AUTOSAR XML (schema 4-1-3)
standard types defined: uint16, uint32, uint16_DataConstr, uint32_DataConstr, boolean, uint8
package /UAES/ASW/CompuMethods
  compu method CM_boolean: 0=FALSE, 1=TRUE
package /UAES/ASW/DataConstrs
  range DC_boolean: raw 0..1
  range DC_uint16: phys 0..6553.5, raw 0..65535
package /UAES/ASW/DataTypeMappingSets
  data type mapping set DTMS_HvacBlowr_DD
package /UAES/ASW/PortInterfaces
  client server interface IoHwAb_IoSigDio
    operation Di_Get: possible-error=IoHwAb_IoSigDio/E_NOT_OK
      arg id_u16: type=ImplementationDataTypes/uint16, direction=IN, server-argument-impl-policy=USE-ARGUMENT-TYPE
      arg val_u8: type=uint8, direction=OUT, server-argument-impl-policy=USE-ARGUMENT-TYPE
    operation Do_Set: possible-error=IoHwAb_IoSigDio/E_NOT_OK
      arg id_u16: type=ImplementationDataTypes/uint16, direction=IN, server-argument-impl-policy=USE-ARGUMENT-TYPE
      arg val_u8: type=uint8, direction=IN, server-argument-impl-policy=USE-ARGUMENT-TYPE
    error E_NOT_OK: error-code=1
  client server interface IoHwAb_IoSigPwm
    operation Pwm_SetDuty: possible-error=IoHwAb_IoSigPwm/E_NOT_OK
      arg id_u16: type=ImplementationDataTypes/uint16, direction=IN, server-argument-impl-policy=USE-ARGUMENT-TYPE
      arg duty_u16: type=ImplementationDataTypes/uint16, direction=IN, server-argument-impl-policy=USE-ARGUMENT-TYPE
    operation Pwm_SetPerd: possible-error=IoHwAb_IoSigPwm/E_NOT_OK
      arg id_u16: type=ImplementationDataTypes/uint16, direction=IN, server-argument-impl-policy=USE-ARGUMENT-TYPE
      arg perd_u32: type=uint32, direction=IN, server-argument-impl-policy=USE-ARGUMENT-TYPE
    operation Pwm_SetPerdAndDuty: possible-error=IoHwAb_IoSigPwm/E_NOT_OK
      arg id_u16: type=ImplementationDataTypes/uint16, direction=IN, server-argument-impl-policy=USE-ARGUMENT-TYPE
      arg perd_u32: type=uint32, direction=IN, server-argument-impl-policy=USE-ARGUMENT-TYPE
      arg duty_u16: type=ImplementationDataTypes/uint16, direction=IN, server-argument-impl-policy=USE-ARGUMENT-TYPE
    error E_NOT_OK: error-code=1
  13 x sender receiver interface:
    gCFG_u8BlowrCtrlFreqTyp: invalidation-policy{data-element=gCFG_u8BlowrCtrlFreqTyp/Val, handle-invalid=DONT-INVALIDATE}
      data Val: sw-calibration-access=READ-ONLY, type=uint8
    gCFG_u8BlowrCtrlTyp: invalidation-policy{data-element=gCFG_u8BlowrCtrlTyp/Val, handle-invalid=DONT-INVALIDATE}
      data Val: sw-calibration-access=READ-ONLY, type=uint8
    gCFG_u8ReBlowrCtrlFreqTyp: invalidation-policy{data-element=gCFG_u8ReBlowrCtrlFreqTyp/Val, handle-invalid=DONT-INVALIDATE}
      data Val: sw-calibration-access=READ-ONLY, type=uint8
    gCFG_u8ReBlowrCtrlTyp: invalidation-policy{data-element=gCFG_u8ReBlowrCtrlTyp/Val, handle-invalid=DONT-INVALIDATE}
      data Val: sw-calibration-access=READ-ONLY, type=uint8
    gPRM_u8VehicleTypeCfg: invalidation-policy{data-element=gPRM_u8VehicleTypeCfg/Val, handle-invalid=DONT-INVALIDATE}
      data Val: sw-calibration-access=READ-ONLY, range raw 0..255, type=uint8
    HvacBlowr_bLPMBlowrEna: invalidation-policy{data-element=HvacBlowr_bLPMBlowrEna/Val, handle-invalid=DONT-INVALIDATE}
      data Val: sw-calibration-access=READ-ONLY, type=boolean
    HvacBlowr_bReLPMBlowrEna: invalidation-policy{data-element=HvacBlowr_bReLPMBlowrEna/Val, handle-invalid=DONT-INVALIDATE}
      data Val: sw-calibration-access=READ-ONLY, type=boolean
    HvacBlowr_freqPWMBlowr: invalidation-policy{data-element=HvacBlowr_freqPWMBlowr/Val, handle-invalid=DONT-INVALIDATE}
      data Val: sw-calibration-access=READ-ONLY, type=ImplementationDataTypes/uint16
    HvacBlowr_freqRePWMBlowr: invalidation-policy{data-element=HvacBlowr_freqRePWMBlowr/Val, handle-invalid=DONT-INVALIDATE}
      data Val: sw-calibration-access=READ-ONLY, type=ImplementationDataTypes/uint16
    HvacBlowr_ratLPMBlowr: invalidation-policy{data-element=HvacBlowr_ratLPMBlowr/Val, handle-invalid=DONT-INVALIDATE}
      data Val: sw-calibration-access=READ-ONLY, type=ImplementationDataTypes/uint16
    HvacBlowr_ratPWMBlowr: invalidation-policy{data-element=HvacBlowr_ratPWMBlowr/Val, handle-invalid=DONT-INVALIDATE}
      data Val: sw-calibration-access=READ-ONLY, type=ImplementationDataTypes/uint16
    HvacBlowr_ratReLPMBlowr: invalidation-policy{data-element=HvacBlowr_ratReLPMBlowr/Val, handle-invalid=DONT-INVALIDATE}
      data Val: sw-calibration-access=READ-ONLY, type=ImplementationDataTypes/uint16
    HvacBlowr_ratRePWMBlowr: invalidation-policy{data-element=HvacBlowr_ratRePWMBlowr/Val, handle-invalid=DONT-INVALIDATE}
      data Val: sw-calibration-access=READ-ONLY, type=ImplementationDataTypes/uint16
package /UAES/ASW/SwComponentTypes
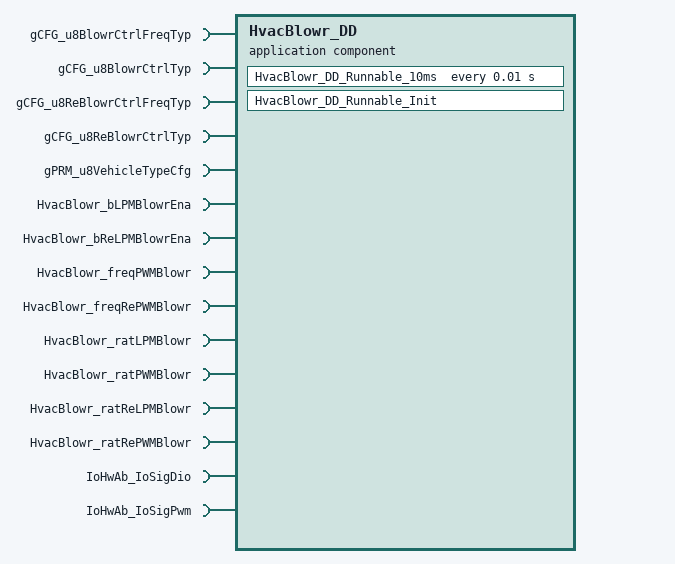
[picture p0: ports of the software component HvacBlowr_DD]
  application sw component type HvacBlowr_DD
    15 x require port:
      gCFG_u8BlowrCtrlFreqTyp: nonqueued-receiver-com-spec{data-element=gCFG_u8BlowrCtrlFreqTyp/Val, filter=data-filter-type=ALWAYS, init-value=0}, required-interface=gCFG_u8BlowrCtrlFreqTyp
      gCFG_u8BlowrCtrlTyp: nonqueued-receiver-com-spec{data-element=gCFG_u8BlowrCtrlTyp/Val, filter=data-filter-type=ALWAYS, init-value=0}, required-interface=gCFG_u8BlowrCtrlTyp
      gCFG_u8ReBlowrCtrlFreqTyp: nonqueued-receiver-com-spec{data-element=gCFG_u8ReBlowrCtrlFreqTyp/Val, filter=data-filter-type=ALWAYS, init-value=0}, required-interface=gCFG_u8ReBlowrCtrlFreqTyp
      gCFG_u8ReBlowrCtrlTyp: nonqueued-receiver-com-spec{data-element=gCFG_u8ReBlowrCtrlTyp/Val, filter=data-filter-type=ALWAYS, init-value=0}, required-interface=gCFG_u8ReBlowrCtrlTyp
      gPRM_u8VehicleTypeCfg: nonqueued-receiver-com-spec{data-element=gPRM_u8VehicleTypeCfg/Val, filter=data-filter-type=ALWAYS, init-value=0}, required-interface=gPRM_u8VehicleTypeCfg
      HvacBlowr_bLPMBlowrEna: nonqueued-receiver-com-spec{data-element=HvacBlowr_bLPMBlowrEna/Val, filter=data-filter-type=ALWAYS, init-value=0}, required-interface=HvacBlowr_bLPMBlowrEna
      HvacBlowr_bReLPMBlowrEna: nonqueued-receiver-com-spec{data-element=HvacBlowr_bReLPMBlowrEna/Val, filter=data-filter-type=ALWAYS, init-value=0}, required-interface=HvacBlowr_bReLPMBlowrEna
      HvacBlowr_freqPWMBlowr: nonqueued-receiver-com-spec{data-element=HvacBlowr_freqPWMBlowr/Val, filter=data-filter-type=ALWAYS, init-value=0}, required-interface=HvacBlowr_freqPWMBlowr
      HvacBlowr_freqRePWMBlowr: nonqueued-receiver-com-spec{data-element=HvacBlowr_freqRePWMBlowr/Val, filter=data-filter-type=ALWAYS, init-value=0}, required-interface=HvacBlowr_freqRePWMBlowr
      HvacBlowr_ratLPMBlowr: nonqueued-receiver-com-spec{data-element=HvacBlowr_ratLPMBlowr/Val, filter=data-filter-type=ALWAYS, init-value=0}, required-interface=HvacBlowr_ratLPMBlowr
      HvacBlowr_ratPWMBlowr: nonqueued-receiver-com-spec{data-element=HvacBlowr_ratPWMBlowr/Val, filter=data-filter-type=ALWAYS, init-value=0}, required-interface=HvacBlowr_ratPWMBlowr
      HvacBlowr_ratReLPMBlowr: nonqueued-receiver-com-spec{data-element=HvacBlowr_ratReLPMBlowr/Val, filter=data-filter-type=ALWAYS, init-value=0}, required-interface=HvacBlowr_ratReLPMBlowr
      HvacBlowr_ratRePWMBlowr: nonqueued-receiver-com-spec{data-element=HvacBlowr_ratRePWMBlowr/Val, filter=data-filter-type=ALWAYS, init-value=0}, required-interface=HvacBlowr_ratRePWMBlowr
      IoHwAb_IoSigDio: required-com-specs=[Di_Get, Do_Set], required-interface=IoHwAb_IoSigDio
      IoHwAb_IoSigPwm: required-com-specs=[Pwm_SetDuty, Pwm_SetPerd, Pwm_SetPerdAndDuty], required-interface=IoHwAb_IoSigPwm
    behavior HvacBlowr_DD_InternalBehavior: data-type-mapping=DTMS_HvacBlowr_DD
      timing event TMT_HvacBlowr_DD_Runnable_10ms: start-on-event=HvacBlowr_DD_Runnable_10ms, period=0.01
      init event HvacBlowr_DD_Runnable_InitEvent: start-on-event=HvacBlowr_DD_Runnable_Init
      runnable HvacBlowr_DD_Runnable_10ms
        data-read-access:
          13 x access:
            READ_gCFG_u8BlowrCtrlFreqTyp_Val: accessed-variable=gCFG_u8BlowrCtrlFreqTyp.Val
            READ_gCFG_u8BlowrCtrlTyp_Val: accessed-variable=gCFG_u8BlowrCtrlTyp.Val
            READ_gCFG_u8ReBlowrCtrlFreqTyp_Val: accessed-variable=gCFG_u8ReBlowrCtrlFreqTyp.Val
            READ_gCFG_u8ReBlowrCtrlTyp_Val: accessed-variable=gCFG_u8ReBlowrCtrlTyp.Val
            READ_gPRM_u8VehicleTypeCfg_Val: accessed-variable=gPRM_u8VehicleTypeCfg.Val
            READ_HvacBlowr_bLPMBlowrEna_Val: accessed-variable=HvacBlowr_bLPMBlowrEna.Val
            READ_HvacBlowr_bReLPMBlowrEna_Val: accessed-variable=HvacBlowr_bReLPMBlowrEna.Val
            READ_HvacBlowr_freqPWMBlowr_Val: accessed-variable=HvacBlowr_freqPWMBlowr.Val
            READ_HvacBlowr_freqRePWMBlowr_Val: accessed-variable=HvacBlowr_freqRePWMBlowr.Val
            READ_HvacBlowr_ratLPMBlowr_Val: accessed-variable=HvacBlowr_ratLPMBlowr.Val
            READ_HvacBlowr_ratPWMBlowr_Val: accessed-variable=HvacBlowr_ratPWMBlowr.Val
            READ_HvacBlowr_ratReLPMBlowr_Val: accessed-variable=HvacBlowr_ratReLPMBlowr.Val
            READ_HvacBlowr_ratRePWMBlowr_Val: accessed-variable=HvacBlowr_ratRePWMBlowr.Val
        sync call SC_IoHwAb_IoSigDio_Do_Set: operation=IoHwAb_IoSigDio.Do_Set, timeout=0
        sync call SC_IoHwAb_IoSigPwm_Pwm_SetDuty: operation=IoHwAb_IoSigPwm.Pwm_SetDuty, timeout=0
        sync call SC_IoHwAb_IoSigPwm_Pwm_SetPerdAndDuty: operation=IoHwAb_IoSigPwm.Pwm_SetPerdAndDuty, timeout=0
      runnable HvacBlowr_DD_Runnable_Init
        data-read-access:
          13 x access:
            READ_gCFG_u8BlowrCtrlFreqTyp_Val: accessed-variable=gCFG_u8BlowrCtrlFreqTyp.Val
            READ_gCFG_u8BlowrCtrlTyp_Val: accessed-variable=gCFG_u8BlowrCtrlTyp.Val
            READ_gCFG_u8ReBlowrCtrlFreqTyp_Val: accessed-variable=gCFG_u8ReBlowrCtrlFreqTyp.Val
            READ_gCFG_u8ReBlowrCtrlTyp_Val: accessed-variable=gCFG_u8ReBlowrCtrlTyp.Val
            READ_gPRM_u8VehicleTypeCfg_Val: accessed-variable=gPRM_u8VehicleTypeCfg.Val
            READ_HvacBlowr_bLPMBlowrEna_Val: accessed-variable=HvacBlowr_bLPMBlowrEna.Val
            READ_HvacBlowr_bReLPMBlowrEna_Val: accessed-variable=HvacBlowr_bReLPMBlowrEna.Val
            READ_HvacBlowr_freqPWMBlowr_Val: accessed-variable=HvacBlowr_freqPWMBlowr.Val
            READ_HvacBlowr_freqRePWMBlowr_Val: accessed-variable=HvacBlowr_freqRePWMBlowr.Val
            READ_HvacBlowr_ratLPMBlowr_Val: accessed-variable=HvacBlowr_ratLPMBlowr.Val
            READ_HvacBlowr_ratPWMBlowr_Val: accessed-variable=HvacBlowr_ratPWMBlowr.Val
            READ_HvacBlowr_ratReLPMBlowr_Val: accessed-variable=HvacBlowr_ratReLPMBlowr.Val
            READ_HvacBlowr_ratRePWMBlowr_Val: accessed-variable=HvacBlowr_ratRePWMBlowr.Val
        sync call SC_IoHwAb_IoSigDio_Do_Set: operation=IoHwAb_IoSigDio.Do_Set, timeout=0
        sync call SC_IoHwAb_IoSigPwm_Pwm_SetDuty: operation=IoHwAb_IoSigPwm.Pwm_SetDuty, timeout=0
        sync call SC_IoHwAb_IoSigPwm_Pwm_SetPerdAndDuty: operation=IoHwAb_IoSigPwm.Pwm_SetPerdAndDuty, timeout=0
  swc implementation HvacBlowr_DD_Implementation: behavior=HvacBlowr_DD_InternalBehavior
    code-descriptors:
      code Default: artifact-descriptors=autosar-engineering-object={short-label=Default, category=SWSRC}
package /UAES/ASW/Units
  unit NoUnit: factor-si-to-unit=1, offset-si-to-unit=0
